# MK20D5 register map
File version: 1.6
Registers are 8-bit, read-write, reset 0x0 unless marked. A register's access mark holds for its fields unless they carry their own. Offsets are from the block's base; [hi:lo] are bit positions.

## RTC — Secure Real Time Clock
Base 0x4003D000; register names take the prefix RTC_
0x00 TSR 32-bit — RTC Time Seconds Register
  [31:0] TSR — Time Seconds Register
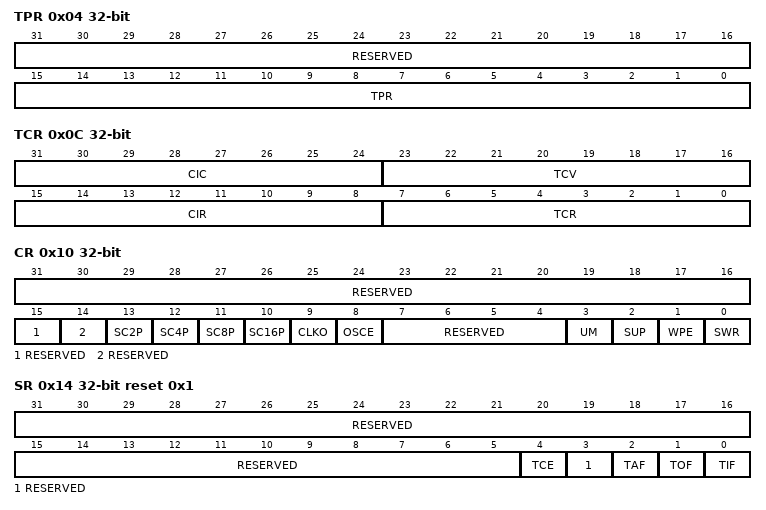
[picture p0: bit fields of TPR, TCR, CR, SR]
0x04 TPR 32-bit access per field — RTC Time Prescaler Register
  [31:16] RESERVED ro
  [15:0] TPR rw — Time Prescaler Register
0x08 TAR 32-bit — RTC Time Alarm Register
  [31:0] TAR — Time Alarm Register
0x0C TCR 32-bit access per field — RTC Time Compensation Register
  [31:24] CIC ro — Compensation Interval Counter
  [23:16] TCV ro — Time Compensation Value
  [15:8] CIR rw — Compensation Interval Register
  [7:0] TCR rw — Time Compensation Register
    128=Time prescaler register overflows every 32896 clock cycles; 255=Time prescaler register overflows every 32769 clock cycles; 0=Time prescaler register overflows every 32768 clock cycles; 1=Time prescaler register overflows every 32767 clock cycles; 127=Time prescaler register overflows every 32641 clock cycles
0x10 CR 32-bit access per field — RTC Control Register
  [31:15] RESERVED ro
  [14] RESERVED ro
  [13] SC2P rw — Oscillator 2pF load configure
    0=Disable the load; 1=Enable the additional load
  [12] SC4P rw — Oscillator 4pF load configure
    0=Disable the load; 1=Enable the additional load
  [11] SC8P rw — Oscillator 8pF load configure
    0=Disable the load; 1=Enable the additional load
  [10] SC16P rw — Oscillator 16pF load configure
    0=Disable the load; 1=Enable the additional load
  [9] CLKO rw — Clock Output
    0=The 32kHz clock is output to other peripherals; 1=The 32kHz clock is not output to other peripherals
  [8] OSCE rw — Oscillator Enable
    0=32.768 kHz oscillator is disabled; 1=32.768 kHz oscillator is enabled. After setting this bit, wait the oscillator startup time before enabling the time counter to allow the 32.768 kHz clock time to stabilize.
  [7:4] RESERVED ro
  [3] UM rw — Update Mode
    0=Registers cannot be written when locked; 1=Registers can be written when locked under limited conditions
  [2] SUP rw — Supervisor Access
    0=Non-supervisor mode write accesses are not supported and generate a bus error; 1=Non-supervisor mode write accesses are supported
  [1] WPE rw — Wakeup Pin Enable
    0=Wakeup pin is disabled; 1=Wakeup pin is enabled and wakeup pin asserts if the RTC interrupt asserts and the chip is powered down
  [0] SWR rw — Software Reset
    0=No effect; 1=Resets all RTC registers except for the SWR bit and the RTC_WAR and RTC_RAR registers. The SWR bit is cleared after VBAT POR and by software explicitly clearing it.
0x14 SR 32-bit access per field reset 0x1 — RTC Status Register
  [31:5] RESERVED ro
  [4] TCE rw — Time Counter Enable
    0=Time counter is disabled; 1=Time counter is enabled
  [3] RESERVED ro
  [2] TAF ro — Time Alarm Flag
    0=Time alarm has not occurred; 1=Time alarm has occurred
  [1] TOF ro — Time Overflow Flag
    0=Time overflow has not occurred; 1=Time overflow has occurred and time counter is read as zero
  [0] TIF ro — Time Invalid Flag
    0=Time is valid; 1=Time is invalid and time counter is read as zero
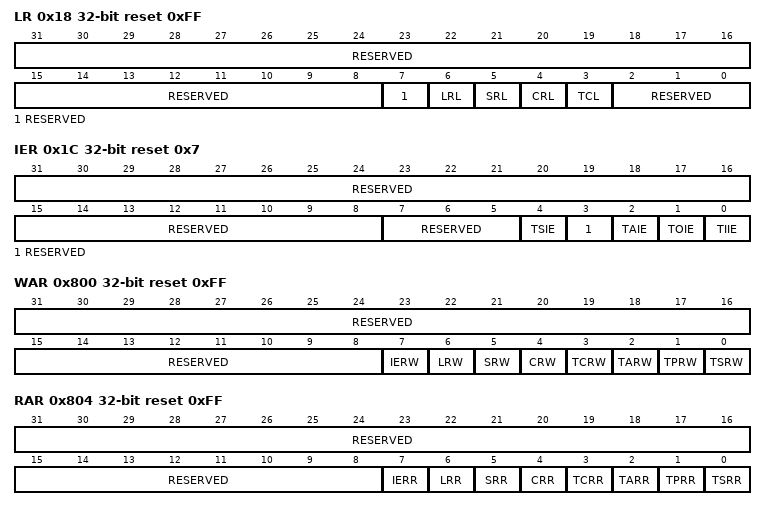
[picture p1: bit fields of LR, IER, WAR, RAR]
0x18 LR 32-bit access per field reset 0xFF — RTC Lock Register
  [31:8] RESERVED ro
  [7] RESERVED ro
  [6] LRL rw — Lock Register Lock
    0=Lock register is locked and writes are ignored; 1=Lock register is not locked and writes complete as normal
  [5] SRL rw — Status Register Lock
    0=Status register is locked and writes are ignored; 1=Status register is not locked and writes complete as normal
  [4] CRL rw — Control Register Lock
    0=Control register is locked and writes are ignored; 1=Control register is not locked and writes complete as normal
  [3] TCL rw — Time Compensation Lock
    0=Time compensation register is locked and writes are ignored; 1=Time compensation register is not locked and writes complete as normal
  [2:0] RESERVED ro
0x1C IER 32-bit access per field reset 0x7 — RTC Interrupt Enable Register
  [31:8] RESERVED ro
  [7:5] RESERVED rw
  [4] TSIE rw — Time Seconds Interrupt Enable
    0=Seconds interrupt is disabled; 1=Seconds interrupt is enabled
  [3] RESERVED rw
  [2] TAIE rw — Time Alarm Interrupt Enable
    0=Time alarm flag does not generate an interrupt; 1=Time alarm flag does generate an interrupt
  [1] TOIE rw — Time Overflow Interrupt Enable
    0=Time overflow flag does not generate an interrupt; 1=Time overflow flag does generate an interrupt
  [0] TIIE rw — Time Invalid Interrupt Enable
    0=Time invalid flag does not generate an interrupt; 1=Time invalid flag does generate an interrupt
0x800 WAR 32-bit access per field reset 0xFF — RTC Write Access Register
  [31:8] RESERVED ro
  [7] IERW rw — Interrupt Enable Register Write
    0=Writes to the interupt enable register are ignored; 1=Writes to the interrupt enable register complete as normal
  [6] LRW rw — Lock Register Write
    0=Writes to the lock register are ignored; 1=Writes to the lock register complete as normal
  [5] SRW rw — Status Register Write
    0=Writes to the status register are ignored; 1=Writes to the status register complete as normal
  [4] CRW rw — Control Register Write
    0=Writes to the control register are ignored; 1=Writes to the control register complete as normal
  [3] TCRW rw — Time Compensation Register Write
    0=Writes to the time compensation register are ignored; 1=Writes to the time compensation register complete as normal
  [2] TARW rw — Time Alarm Register Write
    0=Writes to the time alarm register are ignored; 1=Writes to the time alarm register complete as normal
  [1] TPRW rw — Time Prescaler Register Write
    0=Writes to the time prescaler register are ignored; 1=Writes to the time prescaler register complete as normal
  [0] TSRW rw — Time Seconds Register Write
    0=Writes to the time seconds register are ignored; 1=Writes to the time seconds register complete as normal
0x804 RAR 32-bit access per field reset 0xFF — RTC Read Access Register
  [31:8] RESERVED ro
  [7] IERR rw — Interrupt Enable Register Read
    0=Reads to the interrupt enable register are ignored; 1=Reads to the interrupt enable register complete as normal
  [6] LRR rw — Lock Register Read
    0=Reads to the lock register are ignored; 1=Reads to the lock register complete as normal
  [5] SRR rw — Status Register Read
    0=Reads to the status register are ignored; 1=Reads to the status register complete as normal
  [4] CRR rw — Control Register Read
    0=Reads to the control register are ignored; 1=Reads to the control register complete as normal
  [3] TCRR rw — Time Compensation Register Read
    0=Reads to the time compensation register are ignored; 1=Reads to the time compensation register complete as normal
  [2] TARR rw — Time Alarm Register Read
    0=Reads to the time alarm register are ignored; 1=Reads to the time alarm register complete as normal
  [1] TPRR rw — Time Prescaler Register Read
    0=Reads to the time prescaler register are ignored; 1=Reads to the time prescaler register complete as normal
  [0] TSRR rw — Time Seconds Register Read
    0=Reads to the time seconds register are ignored; 1=Reads to the time seconds register complete as normal
